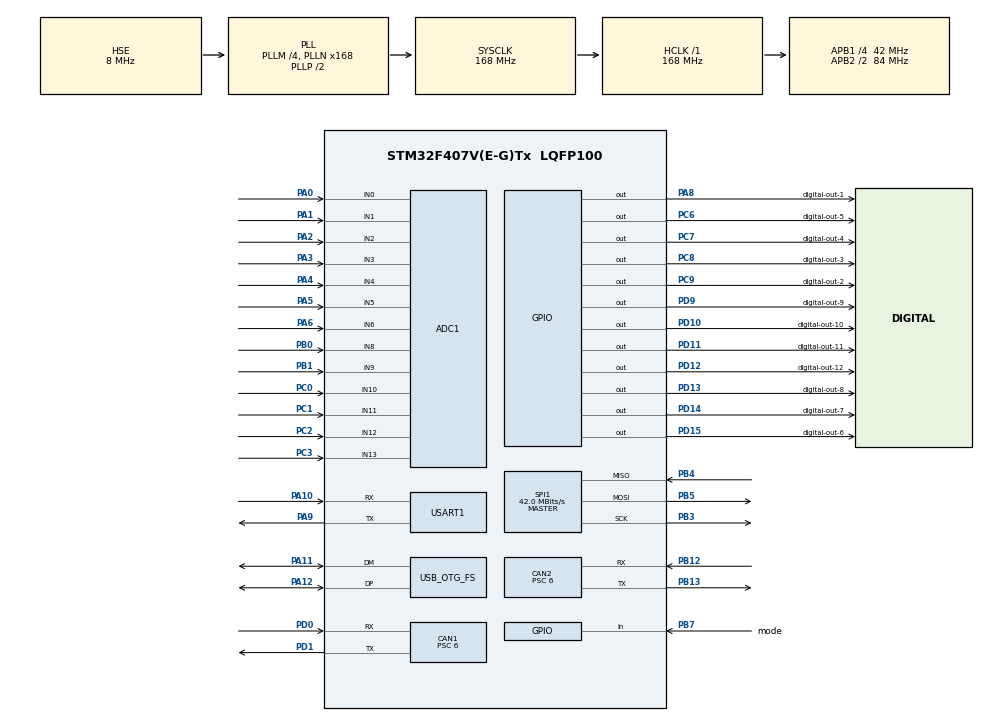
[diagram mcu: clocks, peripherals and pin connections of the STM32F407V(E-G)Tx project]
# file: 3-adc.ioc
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ADC1.Channel-0\#ChannelRegularConversion=ADC_CHANNEL_0
ADC1.Channel-1\#ChannelRegularConversion=ADC_CHANNEL_1
ADC1.Channel-10\#ChannelRegularConversion=ADC_CHANNEL_8
ADC1.Channel-11\#ChannelRegularConversion=ADC_CHANNEL_9
ADC1.Channel-2\#ChannelRegularConversion=ADC_CHANNEL_2
ADC1.Channel-3\#ChannelRegularConversion=ADC_CHANNEL_3
ADC1.Channel-4\#ChannelRegularConversion=ADC_CHANNEL_4
ADC1.Channel-5\#ChannelRegularConversion=ADC_CHANNEL_5
ADC1.Channel-6\#ChannelRegularConversion=ADC_CHANNEL_10
ADC1.Channel-7\#ChannelRegularConversion=ADC_CHANNEL_11
ADC1.Channel-8\#ChannelRegularConversion=ADC_CHANNEL_12
ADC1.Channel-9\#ChannelRegularConversion=ADC_CHANNEL_13
ADC1.ClockPrescaler=ADC_CLOCK_SYNC_PCLK_DIV4
ADC1.ContinuousConvMode=ENABLE
ADC1.DMAContinuousRequests=ENABLE
ADC1.DiscontinuousConvMode=DISABLE
ADC1.EOCSelection=ADC_EOC_SEQ_CONV
ADC1.InjNumberOfConversion=0
ADC1.NbrOfConversion=12
ADC1.NbrOfConversionFlag=1
ADC1.Rank-0\#ChannelRegularConversion=1
ADC1.Rank-1\#ChannelRegularConversion=2
ADC1.Rank-10\#ChannelRegularConversion=11
ADC1.Rank-11\#ChannelRegularConversion=12
ADC1.Rank-2\#ChannelRegularConversion=3
ADC1.Rank-3\#ChannelRegularConversion=4
ADC1.Rank-4\#ChannelRegularConversion=5
ADC1.Rank-5\#ChannelRegularConversion=6
ADC1.Rank-6\#ChannelRegularConversion=7
ADC1.Rank-7\#ChannelRegularConversion=8
ADC1.Rank-8\#ChannelRegularConversion=9
ADC1.Rank-9\#ChannelRegularConversion=10
ADC1.SamplingTime-0\#ChannelRegularConversion=ADC_SAMPLETIME_144CYCLES
ADC1.SamplingTime-1\#ChannelRegularConversion=ADC_SAMPLETIME_144CYCLES
ADC1.SamplingTime-10\#ChannelRegularConversion=ADC_SAMPLETIME_144CYCLES
ADC1.SamplingTime-11\#ChannelRegularConversion=ADC_SAMPLETIME_144CYCLES
ADC1.SamplingTime-2\#ChannelRegularConversion=ADC_SAMPLETIME_144CYCLES
ADC1.SamplingTime-3\#ChannelRegularConversion=ADC_SAMPLETIME_144CYCLES
ADC1.SamplingTime-4\#ChannelRegularConversion=ADC_SAMPLETIME_144CYCLES
ADC1.SamplingTime-5\#ChannelRegularConversion=ADC_SAMPLETIME_144CYCLES
ADC1.SamplingTime-6\#ChannelRegularConversion=ADC_SAMPLETIME_144CYCLES
ADC1.SamplingTime-7\#ChannelRegularConversion=ADC_SAMPLETIME_144CYCLES
ADC1.SamplingTime-8\#ChannelRegularConversion=ADC_SAMPLETIME_144CYCLES
ADC1.SamplingTime-9\#ChannelRegularConversion=ADC_SAMPLETIME_144CYCLES
ADC1.ScanConvMode=ENABLE
ADC1.master=1
CAN1.ABOM=ENABLE
CAN1.BS1=CAN_BS1_11TQ
CAN1.BS2=CAN_BS2_2TQ
CAN1.CalculateBaudRate=500000
CAN1.CalculateTimeBit=2000
CAN1.CalculateTimeQuantum=142.85714285714286
CAN1.NART=ENABLE
CAN1.Prescaler=6
CAN1.SJW=CAN_SJW_1TQ
CAN1.TXFP=ENABLE
CAN2.ABOM=ENABLE
CAN2.BS1=CAN_BS1_11TQ
CAN2.BS2=CAN_BS2_2TQ
CAN2.CalculateBaudRate=500000
CAN2.CalculateTimeBit=2000
CAN2.CalculateTimeQuantum=142.85714285714286
CAN2.NART=ENABLE
CAN2.Prescaler=6
CAN2.TXFP=ENABLE
Dma.ADC1.0.Direction=DMA_PERIPH_TO_MEMORY
Dma.ADC1.0.FIFOMode=DMA_FIFOMODE_DISABLE
Dma.ADC1.0.Instance=DMA2_Stream0
Dma.ADC1.0.MemDataAlignment=DMA_MDATAALIGN_HALFWORD
Dma.ADC1.0.MemInc=DMA_MINC_ENABLE
Dma.ADC1.0.Mode=DMA_CIRCULAR
Dma.ADC1.0.PeriphDataAlignment=DMA_PDATAALIGN_HALFWORD
Dma.ADC1.0.PeriphInc=DMA_PINC_DISABLE
Dma.ADC1.0.Priority=DMA_PRIORITY_HIGH
Dma.Request0=ADC1
Mcu.Family=STM32F4
Mcu.Name=STM32F407V(E-G)Tx
Mcu.Package=LQFP100
NVIC.CAN1_RX0_IRQn=true\:0\:0\:false\:false\:true\:true\:true\:true
NVIC.CAN1_TX_IRQn=true\:0\:0\:false\:false\:true\:true\:true\:true
NVIC.CAN2_RX0_IRQn=true\:0\:0\:false\:false\:true\:true\:true\:true
NVIC.CAN2_TX_IRQn=true\:0\:0\:false\:false\:true\:true\:true\:true
NVIC.DMA2_Stream0_IRQn=true\:0\:0\:false\:false\:true\:false\:true\:true
NVIC.PriorityGroup=NVIC_PRIORITYGROUP_4
NVIC.TIM1_UP_TIM10_IRQn=true\:0\:0\:false\:false\:true\:true\:true\:true
PA0-WKUP.Signal=ADCx_IN0
PA1.Signal=ADCx_IN1
PA10.Mode=Asynchronous
PA10.Signal=USART1_RX
PA11.Mode=Host_Only
PA11.Signal=USB_OTG_FS_DM
PA12.Mode=Host_Only
PA12.Signal=USB_OTG_FS_DP
PA13.Mode=Serial_Wire
PA13.Signal=SYS_JTMS-SWDIO
PA14.Mode=Serial_Wire
PA14.Signal=SYS_JTCK-SWCLK
PA2.Signal=ADCx_IN2
PA3.Signal=ADCx_IN3
PA4.Signal=ADCx_IN4
PA5.Signal=ADCx_IN5
PA6.Signal=ADCx_IN6
PA8.GPIO_Label=digital-out-1
PA8.Signal=GPIO_Output
PA9.Mode=Asynchronous
PA9.Signal=USART1_TX
PB0.Signal=ADCx_IN8
PB1.Signal=ADCx_IN9
PB12.Mode=CAN_Activate
PB12.Signal=CAN2_RX
PB13.Mode=CAN_Activate
PB13.Signal=CAN2_TX
PB3.Mode=Full_Duplex_Master
PB3.Signal=SPI1_SCK
PB4.Mode=Full_Duplex_Master
PB4.Signal=SPI1_MISO
PB5.Mode=Full_Duplex_Master
PB5.Signal=SPI1_MOSI
PB7.GPIO_Label=mode
PB7.Signal=GPIO_Input
PC0.Signal=ADCx_IN10
PC1.Signal=ADCx_IN11
PC2.Signal=ADCx_IN12
PC3.Signal=ADCx_IN13
PC6.GPIO_Label=digital-out-5
PC6.Signal=GPIO_Output
PC7.GPIO_Label=digital-out-4
PC7.Signal=GPIO_Output
PC8.GPIO_Label=digital-out-3
PC8.Signal=GPIO_Output
PC9.GPIO_Label=digital-out-2
PC9.Signal=GPIO_Output
PD0.Mode=CAN_Activate
PD0.Signal=CAN1_RX
PD1.Mode=CAN_Activate
PD1.Signal=CAN1_TX
PD10.GPIO_Label=digital-out-10
PD10.Signal=GPIO_Output
PD11.GPIO_Label=digital-out-11
PD11.Signal=GPIO_Output
PD12.GPIO_Label=digital-out-12
PD12.Signal=GPIO_Output
PD13.GPIO_Label=digital-out-8
PD13.Signal=GPIO_Output
PD14.GPIO_Label=digital-out-7
PD14.Signal=GPIO_Output
PD15.GPIO_Label=digital-out-6
PD15.Signal=GPIO_Output
PD9.GPIO_Label=digital-out-9
PD9.Signal=GPIO_Output
PH0-OSC_IN.Mode=HSE-External-Oscillator
PH0-OSC_IN.Signal=RCC_OSC_IN
PH1-OSC_OUT.Mode=HSE-External-Oscillator
PH1-OSC_OUT.Signal=RCC_OSC_OUT
ProjectManager.HeapSize=0x200
ProjectManager.StackSize=0x400
ProjectManager.TargetToolchain=MDK-ARM V5
RCC.48MHZClocksFreq_Value=48000000
RCC.AHBFreq_Value=168000000
RCC.APB1CLKDivider=RCC_HCLK_DIV4
RCC.APB1Freq_Value=42000000
RCC.APB1TimFreq_Value=84000000
RCC.APB2CLKDivider=RCC_HCLK_DIV2
RCC.APB2Freq_Value=84000000
RCC.APB2TimFreq_Value=168000000
RCC.CortexFreq_Value=168000000
RCC.HCLKFreq_Value=168000000
RCC.HSE_VALUE=8000000
RCC.HSI_VALUE=16000000
RCC.LSE_VALUE=32768
RCC.PLLM=4
RCC.PLLN=168
RCC.PLLQ=7
RCC.SYSCLKFreq_VALUE=168000000
RCC.SYSCLKSource=RCC_SYSCLKSOURCE_PLLCLK
RCC.VCOOutputFreq_Value=336000000
SH.ADCx_IN0.0=ADC1_IN0,IN0
SH.ADCx_IN1.0=ADC1_IN1,IN1
SH.ADCx_IN10.0=ADC1_IN10,IN10
SH.ADCx_IN11.0=ADC1_IN11,IN11
SH.ADCx_IN12.0=ADC1_IN12,IN12
SH.ADCx_IN13.0=ADC1_IN13,IN13
SH.ADCx_IN2.0=ADC1_IN2,IN2
SH.ADCx_IN3.0=ADC1_IN3,IN3
SH.ADCx_IN4.0=ADC1_IN4,IN4
SH.ADCx_IN5.0=ADC1_IN5,IN5
SH.ADCx_IN6.0=ADC1_IN6,IN6
SH.ADCx_IN8.0=ADC1_IN8,IN8
SH.ADCx_IN9.0=ADC1_IN9,IN9
SPI1.BaudRatePrescaler=SPI_BAUDRATEPRESCALER_2
SPI1.CalculateBaudRate=42.0 MBits/s
SPI1.Direction=SPI_DIRECTION_2LINES
SPI1.Mode=SPI_MODE_MASTER
SPI1.VirtualType=VM_MASTER
TIM1.AutoReloadPreload=TIM_AUTORELOAD_PRELOAD_ENABLE
TIM1.Period=99
TIM1.Prescaler=16799
USART1.VirtualMode=VM_ASYNC
USB_OTG_FS.VirtualMode=Host_Only
USB_OTG_FS.phy_itface=HCD_PHY_EMBEDDED
VP_TIM1_VS_ClockSourceINT.Mode=Internal
board=custom

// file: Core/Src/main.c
/* USER CODE BEGIN Header */
/**
  ******************************************************************************
  * @file           : main.c
  * @brief          : Main program body
  ******************************************************************************
  * @attention
  *
  * Copyright (c) 2026 STMicroelectronics.
  * All rights reserved.
  *
  * This software is licensed under terms that can be found in the LICENSE file
  * in the root directory of this software component.
  * If no LICENSE file comes with this software, it is provided AS-IS.
  *
  ******************************************************************************
  */
/* USER CODE END Header */
#include "main.h"

ADC_HandleTypeDef hadc1;
DMA_HandleTypeDef hdma_adc1;

CAN_HandleTypeDef hcan1;
CAN_HandleTypeDef hcan2;

SPI_HandleTypeDef hspi1;

TIM_HandleTypeDef htim1;

UART_HandleTypeDef huart1;

HCD_HandleTypeDef hhcd_USB_OTG_FS;

void SystemClock_Config(void);
static void MX_GPIO_Init(void);
static void MX_DMA_Init(void);
static void MX_ADC1_Init(void);
static void MX_CAN1_Init(void);
static void MX_TIM1_Init(void);
static void MX_CAN2_Init(void);
static void MX_SPI1_Init(void);
static void MX_USART1_UART_Init(void);
static void MX_USB_OTG_FS_HCD_Init(void);

int main(void)
{

  /* MCU Configuration--------------------------------------------------------*/

  /* Reset of all peripherals, Initializes the Flash interface and the Systick. */
  HAL_Init();

  /* Configure the system clock */
  SystemClock_Config();

  /* Initialize all configured peripherals */
  MX_GPIO_Init();
  MX_DMA_Init();
  MX_ADC1_Init();
  MX_CAN1_Init();
  MX_TIM1_Init();
  MX_CAN2_Init();
  MX_SPI1_Init();
  MX_USART1_UART_Init();
  MX_USB_OTG_FS_HCD_Init();
  /* USER CODE BEGIN 2 */
	//DigitalOut_Init(&hadc1);
	CanLink_Init(&hcan1, &hcan2);
  /* USER CODE END 2 */

  /* Infinite loop */
  /* USER CODE BEGIN WHILE */
  while (1)
  {
		 CanLink_Process();
		//DigitalOut_Process();
    /* USER CODE END WHILE */

  }
}

void SystemClock_Config(void)
{
  RCC_OscInitTypeDef RCC_OscInitStruct = {0};
  RCC_ClkInitTypeDef RCC_ClkInitStruct = {0};

  /** Configure the main internal regulator output voltage
  */
  __HAL_RCC_PWR_CLK_ENABLE();
  __HAL_PWR_VOLTAGESCALING_CONFIG(PWR_REGULATOR_VOLTAGE_SCALE1);

  /** Initializes the RCC Oscillators according to the specified parameters
  * in the RCC_OscInitTypeDef structure.
  */
  RCC_OscInitStruct.OscillatorType = RCC_OSCILLATORTYPE_HSE;
  RCC_OscInitStruct.HSEState = RCC_HSE_ON;
  RCC_OscInitStruct.PLL.PLLState = RCC_PLL_ON;
  RCC_OscInitStruct.PLL.PLLSource = RCC_PLLSOURCE_HSE;
  RCC_OscInitStruct.PLL.PLLM = 4;
  RCC_OscInitStruct.PLL.PLLN = 168;
  RCC_OscInitStruct.PLL.PLLP = RCC_PLLP_DIV2;
  RCC_OscInitStruct.PLL.PLLQ = 7;
  if (HAL_RCC_OscConfig(&RCC_OscInitStruct) != HAL_OK)
  {
    Error_Handler();
  }

  /** Initializes the CPU, AHB and APB buses clocks
  */
  RCC_ClkInitStruct.ClockType = RCC_CLOCKTYPE_HCLK|RCC_CLOCKTYPE_SYSCLK
                              |RCC_CLOCKTYPE_PCLK1|RCC_CLOCKTYPE_PCLK2;
  RCC_ClkInitStruct.SYSCLKSource = RCC_SYSCLKSOURCE_PLLCLK;
  RCC_ClkInitStruct.AHBCLKDivider = RCC_SYSCLK_DIV1;
  RCC_ClkInitStruct.APB1CLKDivider = RCC_HCLK_DIV4;
  RCC_ClkInitStruct.APB2CLKDivider = RCC_HCLK_DIV2;

  if (HAL_RCC_ClockConfig(&RCC_ClkInitStruct, FLASH_LATENCY_5) != HAL_OK)
  {
    Error_Handler();
  }
}

static void MX_ADC1_Init(void)
{

  ADC_ChannelConfTypeDef sConfig = {0};

  /** Configure the global features of the ADC (Clock, Resolution, Data Alignment and number of conversion)
  */
  hadc1.Instance = ADC1;
  hadc1.Init.ClockPrescaler = ADC_CLOCK_SYNC_PCLK_DIV4;
  hadc1.Init.Resolution = ADC_RESOLUTION_12B;
  hadc1.Init.ScanConvMode = ENABLE;
  hadc1.Init.ContinuousConvMode = ENABLE;
  hadc1.Init.DiscontinuousConvMode = DISABLE;
  hadc1.Init.ExternalTrigConvEdge = ADC_EXTERNALTRIGCONVEDGE_NONE;
  hadc1.Init.ExternalTrigConv = ADC_SOFTWARE_START;
  hadc1.Init.DataAlign = ADC_DATAALIGN_RIGHT;
  hadc1.Init.NbrOfConversion = 12;
  hadc1.Init.DMAContinuousRequests = ENABLE;
  hadc1.Init.EOCSelection = ADC_EOC_SEQ_CONV;
  if (HAL_ADC_Init(&hadc1) != HAL_OK)
  {
    Error_Handler();
  }

  /** Configure for the selected ADC regular channel its corresponding rank in the sequencer and its sample time.
  */
  sConfig.Channel = ADC_CHANNEL_0;
  sConfig.Rank = 1;
  sConfig.SamplingTime = ADC_SAMPLETIME_144CYCLES;
  if (HAL_ADC_ConfigChannel(&hadc1, &sConfig) != HAL_OK)
  {
    Error_Handler();
  }

  /** Configure for the selected ADC regular channel its corresponding rank in the sequencer and its sample time.
  */
  sConfig.Channel = ADC_CHANNEL_1;
  sConfig.Rank = 2;
  if (HAL_ADC_ConfigChannel(&hadc1, &sConfig) != HAL_OK)
  {
    Error_Handler();
  }

  /** Configure for the selected ADC regular channel its corresponding rank in the sequencer and its sample time.
  */
  sConfig.Channel = ADC_CHANNEL_2;
  sConfig.Rank = 3;
  if (HAL_ADC_ConfigChannel(&hadc1, &sConfig) != HAL_OK)
  {
    Error_Handler();
  }

  /** Configure for the selected ADC regular channel its corresponding rank in the sequencer and its sample time.
  */
  sConfig.Channel = ADC_CHANNEL_3;
  sConfig.Rank = 4;
  if (HAL_ADC_ConfigChannel(&hadc1, &sConfig) != HAL_OK)
  {
    Error_Handler();
  }

  /** Configure for the selected ADC regular channel its corresponding rank in the sequencer and its sample time.
  */
  sConfig.Channel = ADC_CHANNEL_4;
  sConfig.Rank = 5;
  if (HAL_ADC_ConfigChannel(&hadc1, &sConfig) != HAL_OK)
  {
    Error_Handler();
  }

  /** Configure for the selected ADC regular channel its corresponding rank in the sequencer and its sample time.
  */
  sConfig.Channel = ADC_CHANNEL_5;
  sConfig.Rank = 6;
  if (HAL_ADC_ConfigChannel(&hadc1, &sConfig) != HAL_OK)
  {
    Error_Handler();
  }

  /** Configure for the selected ADC regular channel its corresponding rank in the sequencer and its sample time.
  */
  sConfig.Channel = ADC_CHANNEL_10;
  sConfig.Rank = 7;
  if (HAL_ADC_ConfigChannel(&hadc1, &sConfig) != HAL_OK)
  {
    Error_Handler();
  }

  /** Configure for the selected ADC regular channel its corresponding rank in the sequencer and its sample time.
  */
  sConfig.Channel = ADC_CHANNEL_11;
  sConfig.Rank = 8;
  if (HAL_ADC_ConfigChannel(&hadc1, &sConfig) != HAL_OK)
  {
    Error_Handler();
  }

  /** Configure for the selected ADC regular channel its corresponding rank in the sequencer and its sample time.
  */
  sConfig.Channel = ADC_CHANNEL_12;
  sConfig.Rank = 9;
  if (HAL_ADC_ConfigChannel(&hadc1, &sConfig) != HAL_OK)
  {
    Error_Handler();
  }

  /** Configure for the selected ADC regular channel its corresponding rank in the sequencer and its sample time.
  */
  sConfig.Channel = ADC_CHANNEL_13;
  sConfig.Rank = 10;
  if (HAL_ADC_ConfigChannel(&hadc1, &sConfig) != HAL_OK)
  {
    Error_Handler();
  }

  /** Configure for the selected ADC regular channel its corresponding rank in the sequencer and its sample time.
  */
  sConfig.Channel = ADC_CHANNEL_8;
  sConfig.Rank = 11;
  if (HAL_ADC_ConfigChannel(&hadc1, &sConfig) != HAL_OK)
  {
    Error_Handler();
  }

  /** Configure for the selected ADC regular channel its corresponding rank in the sequencer and its sample time.
  */
  sConfig.Channel = ADC_CHANNEL_9;
  sConfig.Rank = 12;
  if (HAL_ADC_ConfigChannel(&hadc1, &sConfig) != HAL_OK)
  {
    Error_Handler();
  }

}

static void MX_CAN1_Init(void)
{

  hcan1.Instance = CAN1;
  hcan1.Init.Prescaler = 6;
  hcan1.Init.Mode = CAN_MODE_NORMAL;
  hcan1.Init.SyncJumpWidth = CAN_SJW_1TQ;
  hcan1.Init.TimeSeg1 = CAN_BS1_11TQ;
  hcan1.Init.TimeSeg2 = CAN_BS2_2TQ;
  hcan1.Init.TimeTriggeredMode = DISABLE;
  hcan1.Init.AutoBusOff = ENABLE;
  hcan1.Init.AutoWakeUp = DISABLE;
  hcan1.Init.AutoRetransmission = ENABLE;
  hcan1.Init.ReceiveFifoLocked = DISABLE;
  hcan1.Init.TransmitFifoPriority = ENABLE;
  if (HAL_CAN_Init(&hcan1) != HAL_OK)
  {
    Error_Handler();
  }

}

static void MX_CAN2_Init(void)
{

  hcan2.Instance = CAN2;
  hcan2.Init.Prescaler = 6;
  hcan2.Init.Mode = CAN_MODE_NORMAL;
  hcan2.Init.SyncJumpWidth = CAN_SJW_1TQ;
  hcan2.Init.TimeSeg1 = CAN_BS1_11TQ;
  hcan2.Init.TimeSeg2 = CAN_BS2_2TQ;
  hcan2.Init.TimeTriggeredMode = DISABLE;
  hcan2.Init.AutoBusOff = ENABLE;
  hcan2.Init.AutoWakeUp = DISABLE;
  hcan2.Init.AutoRetransmission = ENABLE;
  hcan2.Init.ReceiveFifoLocked = DISABLE;
  hcan2.Init.TransmitFifoPriority = ENABLE;
  if (HAL_CAN_Init(&hcan2) != HAL_OK)
  {
    Error_Handler();
  }

}

static void MX_SPI1_Init(void)
{

  /* SPI1 parameter configuration*/
  hspi1.Instance = SPI1;
  hspi1.Init.Mode = SPI_MODE_MASTER;
  hspi1.Init.Direction = SPI_DIRECTION_2LINES;
  hspi1.Init.DataSize = SPI_DATASIZE_8BIT;
  hspi1.Init.CLKPolarity = SPI_POLARITY_LOW;
  hspi1.Init.CLKPhase = SPI_PHASE_1EDGE;
  hspi1.Init.NSS = SPI_NSS_SOFT;
  hspi1.Init.BaudRatePrescaler = SPI_BAUDRATEPRESCALER_2;
  hspi1.Init.FirstBit = SPI_FIRSTBIT_MSB;
  hspi1.Init.TIMode = SPI_TIMODE_DISABLE;
  hspi1.Init.CRCCalculation = SPI_CRCCALCULATION_DISABLE;
  hspi1.Init.CRCPolynomial = 10;
  if (HAL_SPI_Init(&hspi1) != HAL_OK)
  {
    Error_Handler();
  }

}

static void MX_TIM1_Init(void)
{

  TIM_ClockConfigTypeDef sClockSourceConfig = {0};
  TIM_MasterConfigTypeDef sMasterConfig = {0};

  htim1.Instance = TIM1;
  htim1.Init.Prescaler = 16799;
  htim1.Init.CounterMode = TIM_COUNTERMODE_UP;
  htim1.Init.Period = 99;
  htim1.Init.ClockDivision = TIM_CLOCKDIVISION_DIV1;
  htim1.Init.RepetitionCounter = 0;
  htim1.Init.AutoReloadPreload = TIM_AUTORELOAD_PRELOAD_ENABLE;
  if (HAL_TIM_Base_Init(&htim1) != HAL_OK)
  {
    Error_Handler();
  }
  sClockSourceConfig.ClockSource = TIM_CLOCKSOURCE_INTERNAL;
  if (HAL_TIM_ConfigClockSource(&htim1, &sClockSourceConfig) != HAL_OK)
  {
    Error_Handler();
  }
  sMasterConfig.MasterOutputTrigger = TIM_TRGO_RESET;
  sMasterConfig.MasterSlaveMode = TIM_MASTERSLAVEMODE_DISABLE;
  if (HAL_TIMEx_MasterConfigSynchronization(&htim1, &sMasterConfig) != HAL_OK)
  {
    Error_Handler();
  }

}

static void MX_USART1_UART_Init(void)
{

  huart1.Instance = USART1;
  huart1.Init.BaudRate = 115200;
  huart1.Init.WordLength = UART_WORDLENGTH_8B;
  huart1.Init.StopBits = UART_STOPBITS_1;
  huart1.Init.Parity = UART_PARITY_NONE;
  huart1.Init.Mode = UART_MODE_TX_RX;
  huart1.Init.HwFlowCtl = UART_HWCONTROL_NONE;
  huart1.Init.OverSampling = UART_OVERSAMPLING_16;
  if (HAL_UART_Init(&huart1) != HAL_OK)
  {
    Error_Handler();
  }

}

static void MX_USB_OTG_FS_HCD_Init(void)
{

  hhcd_USB_OTG_FS.Instance = USB_OTG_FS;
  hhcd_USB_OTG_FS.Init.Host_channels = 8;
  hhcd_USB_OTG_FS.Init.speed = HCD_SPEED_FULL;
  hhcd_USB_OTG_FS.Init.dma_enable = DISABLE;
  hhcd_USB_OTG_FS.Init.phy_itface = HCD_PHY_EMBEDDED;
  hhcd_USB_OTG_FS.Init.Sof_enable = DISABLE;
  if (HAL_HCD_Init(&hhcd_USB_OTG_FS) != HAL_OK)
  {
    Error_Handler();
  }

}

static void MX_DMA_Init(void)
{

  /* DMA controller clock enable */
  __HAL_RCC_DMA2_CLK_ENABLE();

  /* DMA interrupt init */
  /* DMA2_Stream0_IRQn interrupt configuration */
  HAL_NVIC_SetPriority(DMA2_Stream0_IRQn, 0, 0);
  HAL_NVIC_EnableIRQ(DMA2_Stream0_IRQn);

}

static void MX_GPIO_Init(void)
{
  GPIO_InitTypeDef GPIO_InitStruct = {0};

  /* GPIO Ports Clock Enable */
  __HAL_RCC_GPIOH_CLK_ENABLE();
  __HAL_RCC_GPIOC_CLK_ENABLE();
  __HAL_RCC_GPIOA_CLK_ENABLE();
  __HAL_RCC_GPIOB_CLK_ENABLE();
  __HAL_RCC_GPIOD_CLK_ENABLE();

  /*Configure GPIO pin Output Level */
  HAL_GPIO_WritePin(GPIOD, digital_out_9_Pin|digital_out_10_Pin|digital_out_11_Pin|digital_out_12_Pin
                          |digital_out_8_Pin|digital_out_7_Pin|digital_out_6_Pin, GPIO_PIN_RESET);

  /*Configure GPIO pin Output Level */
  HAL_GPIO_WritePin(GPIOC, digital_out_5_Pin|digital_out_4_Pin|digital_out_3_Pin|digital_out_2_Pin, GPIO_PIN_RESET);

  /*Configure GPIO pin Output Level */
  HAL_GPIO_WritePin(digital_out_1_GPIO_Port, digital_out_1_Pin, GPIO_PIN_RESET);

  /*Configure GPIO pins : digital_out_9_Pin digital_out_10_Pin digital_out_11_Pin digital_out_12_Pin
                           digital_out_8_Pin digital_out_7_Pin digital_out_6_Pin */
  GPIO_InitStruct.Pin = digital_out_9_Pin|digital_out_10_Pin|digital_out_11_Pin|digital_out_12_Pin
                          |digital_out_8_Pin|digital_out_7_Pin|digital_out_6_Pin;
  GPIO_InitStruct.Mode = GPIO_MODE_OUTPUT_PP;
  GPIO_InitStruct.Pull = GPIO_NOPULL;
  GPIO_InitStruct.Speed = GPIO_SPEED_FREQ_LOW;
  HAL_GPIO_Init(GPIOD, &GPIO_InitStruct);

  /*Configure GPIO pins : digital_out_5_Pin digital_out_4_Pin digital_out_3_Pin digital_out_2_Pin */
  GPIO_InitStruct.Pin = digital_out_5_Pin|digital_out_4_Pin|digital_out_3_Pin|digital_out_2_Pin;
  GPIO_InitStruct.Mode = GPIO_MODE_OUTPUT_PP;
  GPIO_InitStruct.Pull = GPIO_NOPULL;
  GPIO_InitStruct.Speed = GPIO_SPEED_FREQ_LOW;
  HAL_GPIO_Init(GPIOC, &GPIO_InitStruct);

  /*Configure GPIO pin : digital_out_1_Pin */
  GPIO_InitStruct.Pin = digital_out_1_Pin;
  GPIO_InitStruct.Mode = GPIO_MODE_OUTPUT_PP;
  GPIO_InitStruct.Pull = GPIO_NOPULL;
  GPIO_InitStruct.Speed = GPIO_SPEED_FREQ_LOW;
  HAL_GPIO_Init(digital_out_1_GPIO_Port, &GPIO_InitStruct);

  /*Configure GPIO pin : mode_Pin */
  GPIO_InitStruct.Pin = mode_Pin;
  GPIO_InitStruct.Mode = GPIO_MODE_INPUT;
  GPIO_InitStruct.Pull = GPIO_NOPULL;
  HAL_GPIO_Init(mode_GPIO_Port, &GPIO_InitStruct);

}

void Error_Handler(void)
{
  __disable_irq();
  while (1)
  {
  }
}
